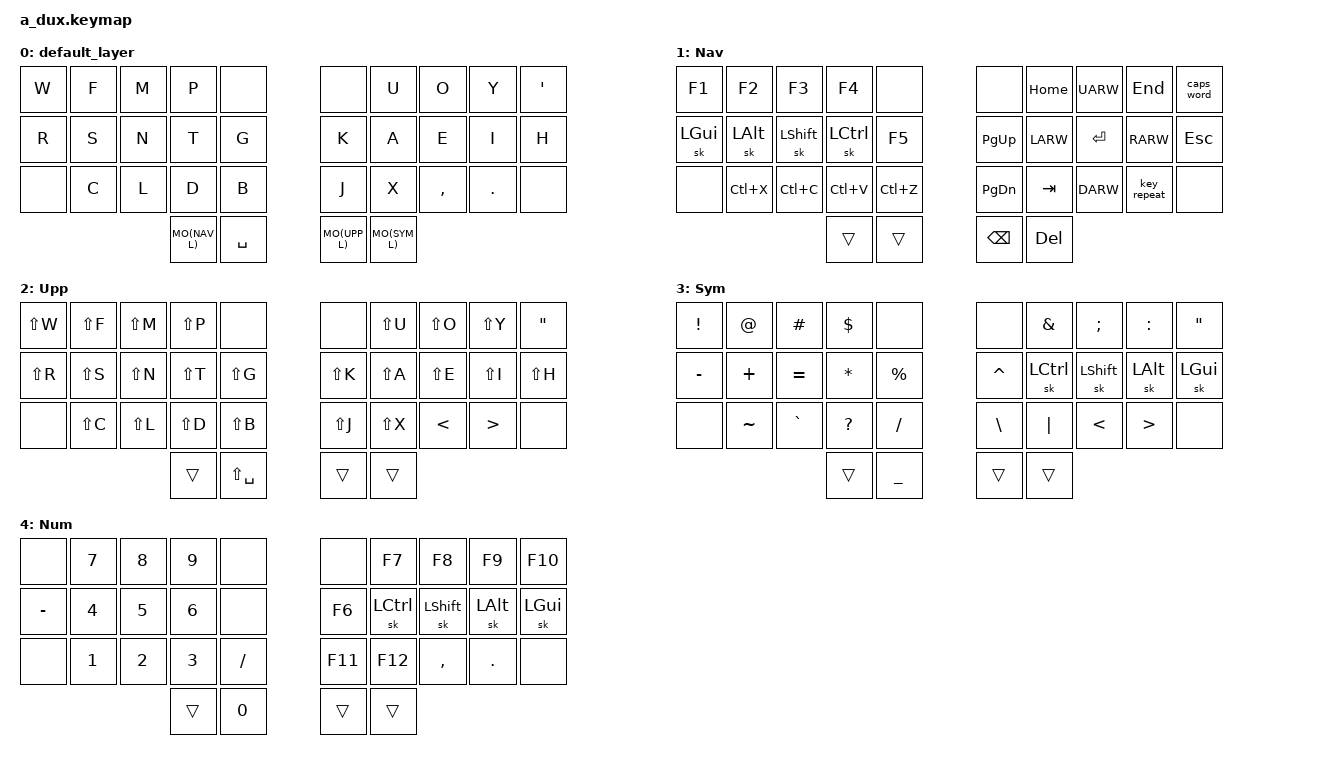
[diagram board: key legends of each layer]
/*
 * Copyright (c) 2020 The ZMK Contributors
 *
 * SPDX-License-Identifier: MIT
 */

#include <behaviors.dtsi>
#include <dt-bindings/zmk/keys.h>

/* Layers */
#define DEF_L 0
#define NAV_L 1
#define UPP_L 2
#define SYM_L 3
#define NUM_L 4

/* Behavior Settings */
&caps_word {
  continue-list = <UNDERSCORE MINUS BACKSPACE>;
};

&sk {
  release-after-ms = <60000>;
};

/ {
    behaviors {
        // A hold-tap that activates without delay (like `&mo`)
        mo_tap: mo_with_tap {
          compatible = "zmk,behavior-hold-tap";
          label = "MO_WITH_TAP";
          #binding-cells = <2>;
          tapping_term_ms = <0>;
          retro-tap;
          flavor = "hold-preferred";
          bindings = <&mo>, <&kp>;
        };
        
        #define MO(LAYER) &mo_tap LAYER F24
        
    };

    combos {
        compatible = "zmk,combos";

        #define COMBO(NAME, BINDINGS, KEYPOS, LAYERS) \
          combo_##NAME { \
            bindings = <BINDINGS>; \
            key-positions = <KEYPOS>; \
            layers = <LAYERS>; \
          };

        /*                KEY POSITIONS

          ╭────────────────────╮ ╭────────────────────╮
          │  0   1   2   3   4 │ │  5   6   7   8   9 │
          │ 10  11  12  13  14 │ │ 15  16  17  18  19 │
          │ 20  21  22  23  24 │ │ 25  26  27  28  29 │
          ╰───────────╮ 30  31 │ │ 32  33 ╭───────────╯
                      ╰────────╯ ╰────────╯            */

         /* Letters */
        COMBO(lower_v, &kp V, 1 2, DEF_L)
        COMBO(lower_q, &kp Q, 1 3, DEF_L)
        COMBO(lower_z, &kp Z, 21 22, DEF_L)
        COMBO(upper_v, &kp LS(V), 1 2, UPP_L)
        COMBO(upper_q, &kp LS(Q), 1 3, UPP_L)
        COMBO(upper_z, &kp LS(Z), 21 22, UPP_L)
        
        /* Brackets */
        COMBO(left_bracket, &kp LBKT, 1 11, DEF_L UPP_L SYM_L NUM_L)
        COMBO(right_bracket, &kp RBKT, 8 18, DEF_L UPP_L SYM_L NUM_L)
        COMBO(left_parenthesis, &kp LPAR, 2 12, DEF_L UPP_L SYM_L NUM_L)
        COMBO(right_parenthesis, &kp RPAR, 7 17, DEF_L UPP_L SYM_L NUM_L)
        COMBO(left_brace, &kp LBRC, 3 13, DEF_L UPP_L SYM_L NUM_L)
        COMBO(right_brace, &kp RBRC, 6 16, DEF_L UPP_L SYM_L NUM_L)

        /* Convenience */
        COMBO(esc, &kp ESC, 3 4, DEF_L)
        COMBO(del, &kp DEL, 13 14, DEF_L)
        COMBO(select_all, &kp LC(A), 21 22, NAV_L)
    };

    conditional_layers {
        compatible = "zmk,conditional-layers";
        tri_layer {
            if-layers = <UPP_L SYM_L>;
            then-layer = <NUM_L>;
        };
    };

    keymap {
        compatible = "zmk,keymap";

        default_layer {
            bindings = <
        // ╭─────────────┬─────────────┬─────────────┬─────────────┬─────────────╮   ╭─────────────┬─────────────┬─────────────┬─────────────┬─────────────╮
             &kp W         &kp F         &kp M         &kp P         &none             &none         &kp U         &kp O         &kp Y         &kp QUOT
             &kp R         &kp S         &kp N         &kp T         &kp G             &kp K         &kp A         &kp E         &kp I         &kp H
             &none         &kp C         &kp L         &kp D         &kp B             &kp J         &kp X         &kp COMMA     &kp DOT       &none
        // ╰─────────────┴─────────────┴─────────────╮                                                           ╭─────────────┴─────────────┴─────────────╯
                                                       MO(NAV_L)     &kp SPACE         MO(UPP_L)     MO(SYM_L)
        //                                           ╰─────────────┴─────────────╯   ╰─────────────┴─────────────╯
               
            >;
        };

        nav_layer {
            label = "Nav";
            bindings = <
        // ╭─────────────┬─────────────┬─────────────┬─────────────┬─────────────╮   ╭─────────────┬─────────────┬─────────────┬─────────────┬─────────────╮
             &kp F1        &kp F2        &kp F3        &kp F4        &none             &none         &kp HOME      &kp UARW      &kp END       &caps_word
             &sk LGUI      &sk LALT      &sk LSHFT     &sk LCTRL     &kp F5            &kp PG_UP     &kp LARW      &kp ENTER     &kp RARW      &kp ESC
             &none         &kp LC(X)     &kp LC(C)     &kp LC(V)     &kp LC(Z)         &kp PG_DN     &kp TAB       &kp DARW      &key_repeat   &none
        // ╰─────────────┴─────────────┴─────────────╮                                                           ╭─────────────┴─────────────┴─────────────╯
                                                       &trans        &trans            &kp BSPC      &kp DEL
        //                                           ╰─────────────┴─────────────╯   ╰─────────────┴─────────────╯
            >;
        };

        upper_layer {
            label = "Upp";
            bindings = <
        // ╭─────────────┬─────────────┬─────────────┬─────────────┬─────────────╮   ╭─────────────┬─────────────┬─────────────┬─────────────┬─────────────╮
             &kp LS(W)     &kp LS(F)     &kp LS(M)     &kp LS(P)     &none             &none         &kp LS(U)     &kp LS(O)     &kp LS(Y)     &kp DQT
             &kp LS(R)     &kp LS(S)     &kp LS(N)     &kp LS(T)     &kp LS(G)         &kp LS(K)     &kp LS(A)     &kp LS(E)     &kp LS(I)     &kp LS(H)
             &none         &kp LS(C)     &kp LS(L)     &kp LS(D)     &kp LS(B)         &kp LS(J)     &kp LS(X)     &kp LT        &kp GT        &none
        // ╰─────────────┴─────────────┴─────────────╮                                                           ╭─────────────┴─────────────┴─────────────╯
                                                       &trans        &kp LS(SPACE)     &trans        &trans
        //                                           ╰─────────────┴─────────────╯   ╰─────────────┴─────────────╯
            >;
        };

        sym_layer {
            label = "Sym";
            bindings = <
        // ╭─────────────┬─────────────┬─────────────┬─────────────┬─────────────╮   ╭─────────────┬─────────────┬─────────────┬─────────────┬─────────────╮
             &kp EXCL      &kp AT        &kp POUND     &kp DLLR      &none             &none         &kp AMPS      &kp SEMI      &kp COLON     &kp DQT
             &kp MINUS     &kp PLUS      &kp EQUAL     &kp ASTRK     &kp PRCNT         &kp CARET     &sk LCTRL     &sk LSHFT     &sk LALT      &sk LGUI
             &none         &kp TILDE     &kp GRAVE     &kp QMARK     &kp FSLH          &kp BSLH      &kp PIPE      &kp LT        &kp GT        &none
        // ╰─────────────┴─────────────┴─────────────╮                                                           ╭─────────────┴─────────────┴─────────────╯
                                                       &trans        &kp UNDER         &trans        &trans
        //                                           ╰─────────────┴─────────────╯   ╰─────────────┴─────────────╯
            >;
        };

        num_layer {
            label = "Num";
            bindings = <
        // ╭─────────────┬─────────────┬─────────────┬─────────────┬─────────────╮   ╭─────────────┬─────────────┬─────────────┬─────────────┬─────────────╮
             &none         &kp N7        &kp N8        &kp N9        &none             &none        &kp F7        &kp F8        &kp F9        &kp F10
             &kp MINUS     &kp N4        &kp N5        &kp N6        &none             &kp F6       &sk LCTRL     &sk LSHFT     &sk LALT      &sk LGUI
             &none         &kp N1        &kp N2        &kp N3        &kp FSLH          &kp F11      &kp F12       &kp COMMA     &kp DOT       &none
        // ╰─────────────┴─────────────┴─────────────╮                                                           ╭─────────────┴─────────────┴─────────────╯
                                                       &trans        &kp N0            &trans        &trans
        //                                           ╰─────────────┴─────────────╯   ╰─────────────┴─────────────╯
            >;
        };
    };
};
